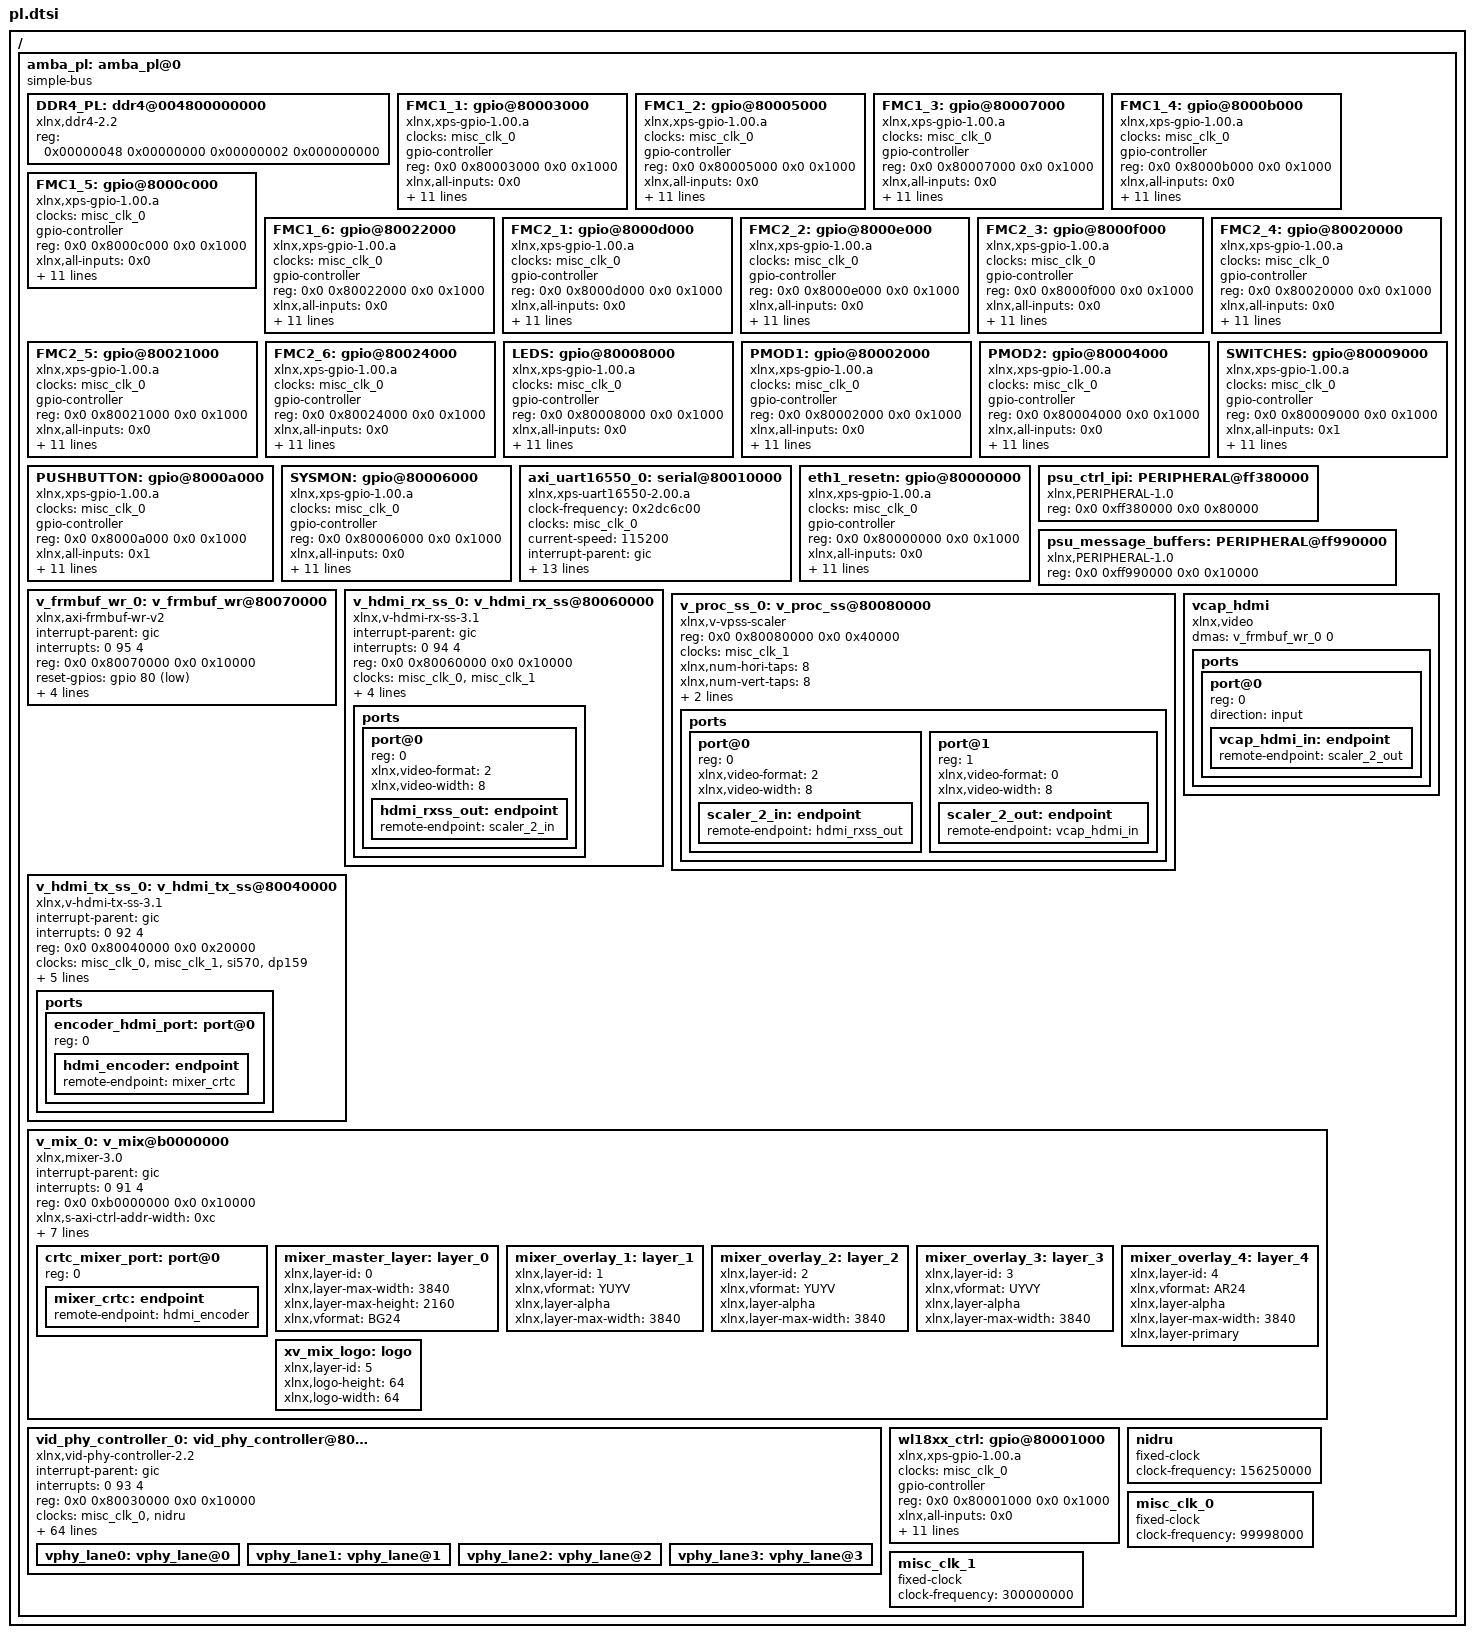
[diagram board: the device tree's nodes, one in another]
/*
 * CAUTION: This file is automatically generated by Xilinx.
 * Version:  
 * Today is: Thu Nov 15 16:52:35 2018
 */


/ {
	amba_pl: amba_pl@0 {
		#address-cells = <2>;
		#size-cells = <2>;
		compatible = "simple-bus";
		ranges ;
		DDR4_PL: ddr4@004800000000 {
			compatible = "xlnx,ddr4-2.2";
			device_type = "memory";
			reg = <0x00000048 0x00000000 0x00000002 0x000000000>;
		};
		FMC1_1: gpio@80003000 {
			#gpio-cells = <3>;
			clock-names = "s_axi_aclk";
			clocks = <&misc_clk_0>;
			compatible = "xlnx,xps-gpio-1.00.a";
			gpio-controller ;
			reg = <0x0 0x80003000 0x0 0x1000>;
			xlnx,all-inputs = <0x0>;
			xlnx,all-inputs-2 = <0x0>;
			xlnx,all-outputs = <0x0>;
			xlnx,all-outputs-2 = <0x0>;
			xlnx,dout-default = <0x00000000>;
			xlnx,dout-default-2 = <0x00000000>;
			xlnx,gpio-width = <0x20>;
			xlnx,gpio2-width = <0x20>;
			xlnx,interrupt-present = <0x0>;
			xlnx,is-dual = <0x0>;
			xlnx,tri-default = <0xFFFFFFFF>;
			xlnx,tri-default-2 = <0xFFFFFFFF>;
		};
		FMC1_2: gpio@80005000 {
			#gpio-cells = <3>;
			clock-names = "s_axi_aclk";
			clocks = <&misc_clk_0>;
			compatible = "xlnx,xps-gpio-1.00.a";
			gpio-controller ;
			reg = <0x0 0x80005000 0x0 0x1000>;
			xlnx,all-inputs = <0x0>;
			xlnx,all-inputs-2 = <0x0>;
			xlnx,all-outputs = <0x0>;
			xlnx,all-outputs-2 = <0x0>;
			xlnx,dout-default = <0x00000000>;
			xlnx,dout-default-2 = <0x00000000>;
			xlnx,gpio-width = <0x20>;
			xlnx,gpio2-width = <0x20>;
			xlnx,interrupt-present = <0x0>;
			xlnx,is-dual = <0x0>;
			xlnx,tri-default = <0xFFFFFFFF>;
			xlnx,tri-default-2 = <0xFFFFFFFF>;
		};
		FMC1_3: gpio@80007000 {
			#gpio-cells = <3>;
			clock-names = "s_axi_aclk";
			clocks = <&misc_clk_0>;
			compatible = "xlnx,xps-gpio-1.00.a";
			gpio-controller ;
			reg = <0x0 0x80007000 0x0 0x1000>;
			xlnx,all-inputs = <0x0>;
			xlnx,all-inputs-2 = <0x0>;
			xlnx,all-outputs = <0x0>;
			xlnx,all-outputs-2 = <0x0>;
			xlnx,dout-default = <0x00000000>;
			xlnx,dout-default-2 = <0x00000000>;
			xlnx,gpio-width = <0x20>;
			xlnx,gpio2-width = <0x20>;
			xlnx,interrupt-present = <0x0>;
			xlnx,is-dual = <0x0>;
			xlnx,tri-default = <0xFFFFFFFF>;
			xlnx,tri-default-2 = <0xFFFFFFFF>;
		};
		FMC1_4: gpio@8000b000 {
			#gpio-cells = <3>;
			clock-names = "s_axi_aclk";
			clocks = <&misc_clk_0>;
			compatible = "xlnx,xps-gpio-1.00.a";
			gpio-controller ;
			reg = <0x0 0x8000b000 0x0 0x1000>;
			xlnx,all-inputs = <0x0>;
			xlnx,all-inputs-2 = <0x0>;
			xlnx,all-outputs = <0x0>;
			xlnx,all-outputs-2 = <0x0>;
			xlnx,dout-default = <0x00000000>;
			xlnx,dout-default-2 = <0x00000000>;
			xlnx,gpio-width = <0x20>;
			xlnx,gpio2-width = <0x20>;
			xlnx,interrupt-present = <0x0>;
			xlnx,is-dual = <0x0>;
			xlnx,tri-default = <0xFFFFFFFF>;
			xlnx,tri-default-2 = <0xFFFFFFFF>;
		};
		FMC1_5: gpio@8000c000 {
			#gpio-cells = <3>;
			clock-names = "s_axi_aclk";
			clocks = <&misc_clk_0>;
			compatible = "xlnx,xps-gpio-1.00.a";
			gpio-controller ;
			reg = <0x0 0x8000c000 0x0 0x1000>;
			xlnx,all-inputs = <0x0>;
			xlnx,all-inputs-2 = <0x0>;
			xlnx,all-outputs = <0x0>;
			xlnx,all-outputs-2 = <0x0>;
			xlnx,dout-default = <0x00000000>;
			xlnx,dout-default-2 = <0x00000000>;
			xlnx,gpio-width = <0x20>;
			xlnx,gpio2-width = <0x20>;
			xlnx,interrupt-present = <0x0>;
			xlnx,is-dual = <0x0>;
			xlnx,tri-default = <0xFFFFFFFF>;
			xlnx,tri-default-2 = <0xFFFFFFFF>;
		};
		FMC1_6: gpio@80022000 {
			#gpio-cells = <3>;
			clock-names = "s_axi_aclk";
			clocks = <&misc_clk_0>;
			compatible = "xlnx,xps-gpio-1.00.a";
			gpio-controller ;
			reg = <0x0 0x80022000 0x0 0x1000>;
			xlnx,all-inputs = <0x0>;
			xlnx,all-inputs-2 = <0x0>;
			xlnx,all-outputs = <0x0>;
			xlnx,all-outputs-2 = <0x0>;
			xlnx,dout-default = <0x00000000>;
			xlnx,dout-default-2 = <0x00000000>;
			xlnx,gpio-width = <0xa>;
			xlnx,gpio2-width = <0x20>;
			xlnx,interrupt-present = <0x0>;
			xlnx,is-dual = <0x0>;
			xlnx,tri-default = <0xFFFFFFFF>;
			xlnx,tri-default-2 = <0xFFFFFFFF>;
		};
		FMC2_1: gpio@8000d000 {
			#gpio-cells = <3>;
			clock-names = "s_axi_aclk";
			clocks = <&misc_clk_0>;
			compatible = "xlnx,xps-gpio-1.00.a";
			gpio-controller ;
			reg = <0x0 0x8000d000 0x0 0x1000>;
			xlnx,all-inputs = <0x0>;
			xlnx,all-inputs-2 = <0x0>;
			xlnx,all-outputs = <0x0>;
			xlnx,all-outputs-2 = <0x0>;
			xlnx,dout-default = <0x00000000>;
			xlnx,dout-default-2 = <0x00000000>;
			xlnx,gpio-width = <0x20>;
			xlnx,gpio2-width = <0x20>;
			xlnx,interrupt-present = <0x0>;
			xlnx,is-dual = <0x0>;
			xlnx,tri-default = <0xFFFFFFFF>;
			xlnx,tri-default-2 = <0xFFFFFFFF>;
		};
		FMC2_2: gpio@8000e000 {
			#gpio-cells = <3>;
			clock-names = "s_axi_aclk";
			clocks = <&misc_clk_0>;
			compatible = "xlnx,xps-gpio-1.00.a";
			gpio-controller ;
			reg = <0x0 0x8000e000 0x0 0x1000>;
			xlnx,all-inputs = <0x0>;
			xlnx,all-inputs-2 = <0x0>;
			xlnx,all-outputs = <0x0>;
			xlnx,all-outputs-2 = <0x0>;
			xlnx,dout-default = <0x00000000>;
			xlnx,dout-default-2 = <0x00000000>;
			xlnx,gpio-width = <0x20>;
			xlnx,gpio2-width = <0x20>;
			xlnx,interrupt-present = <0x0>;
			xlnx,is-dual = <0x0>;
			xlnx,tri-default = <0xFFFFFFFF>;
			xlnx,tri-default-2 = <0xFFFFFFFF>;
		};
		FMC2_3: gpio@8000f000 {
			#gpio-cells = <3>;
			clock-names = "s_axi_aclk";
			clocks = <&misc_clk_0>;
			compatible = "xlnx,xps-gpio-1.00.a";
			gpio-controller ;
			reg = <0x0 0x8000f000 0x0 0x1000>;
			xlnx,all-inputs = <0x0>;
			xlnx,all-inputs-2 = <0x0>;
			xlnx,all-outputs = <0x0>;
			xlnx,all-outputs-2 = <0x0>;
			xlnx,dout-default = <0x00000000>;
			xlnx,dout-default-2 = <0x00000000>;
			xlnx,gpio-width = <0x20>;
			xlnx,gpio2-width = <0x20>;
			xlnx,interrupt-present = <0x0>;
			xlnx,is-dual = <0x0>;
			xlnx,tri-default = <0xFFFFFFFF>;
			xlnx,tri-default-2 = <0xFFFFFFFF>;
		};
		FMC2_4: gpio@80020000 {
			#gpio-cells = <3>;
			clock-names = "s_axi_aclk";
			clocks = <&misc_clk_0>;
			compatible = "xlnx,xps-gpio-1.00.a";
			gpio-controller ;
			reg = <0x0 0x80020000 0x0 0x1000>;
			xlnx,all-inputs = <0x0>;
			xlnx,all-inputs-2 = <0x0>;
			xlnx,all-outputs = <0x0>;
			xlnx,all-outputs-2 = <0x0>;
			xlnx,dout-default = <0x00000000>;
			xlnx,dout-default-2 = <0x00000000>;
			xlnx,gpio-width = <0x20>;
			xlnx,gpio2-width = <0x20>;
			xlnx,interrupt-present = <0x0>;
			xlnx,is-dual = <0x0>;
			xlnx,tri-default = <0xFFFFFFFF>;
			xlnx,tri-default-2 = <0xFFFFFFFF>;
		};
		FMC2_5: gpio@80021000 {
			#gpio-cells = <3>;
			clock-names = "s_axi_aclk";
			clocks = <&misc_clk_0>;
			compatible = "xlnx,xps-gpio-1.00.a";
			gpio-controller ;
			reg = <0x0 0x80021000 0x0 0x1000>;
			xlnx,all-inputs = <0x0>;
			xlnx,all-inputs-2 = <0x0>;
			xlnx,all-outputs = <0x0>;
			xlnx,all-outputs-2 = <0x0>;
			xlnx,dout-default = <0x00000000>;
			xlnx,dout-default-2 = <0x00000000>;
			xlnx,gpio-width = <0x20>;
			xlnx,gpio2-width = <0x20>;
			xlnx,interrupt-present = <0x0>;
			xlnx,is-dual = <0x0>;
			xlnx,tri-default = <0xFFFFFFFF>;
			xlnx,tri-default-2 = <0xFFFFFFFF>;
		};
		FMC2_6: gpio@80024000 {
			#gpio-cells = <3>;
			clock-names = "s_axi_aclk";
			clocks = <&misc_clk_0>;
			compatible = "xlnx,xps-gpio-1.00.a";
			gpio-controller ;
			reg = <0x0 0x80024000 0x0 0x1000>;
			xlnx,all-inputs = <0x0>;
			xlnx,all-inputs-2 = <0x0>;
			xlnx,all-outputs = <0x0>;
			xlnx,all-outputs-2 = <0x0>;
			xlnx,dout-default = <0x00000000>;
			xlnx,dout-default-2 = <0x00000000>;
			xlnx,gpio-width = <0xa>;
			xlnx,gpio2-width = <0x20>;
			xlnx,interrupt-present = <0x0>;
			xlnx,is-dual = <0x0>;
			xlnx,tri-default = <0xFFFFFFFF>;
			xlnx,tri-default-2 = <0xFFFFFFFF>;
		};
		LEDS: gpio@80008000 {
			#gpio-cells = <3>;
			clock-names = "s_axi_aclk";
			clocks = <&misc_clk_0>;
			compatible = "xlnx,xps-gpio-1.00.a";
			gpio-controller ;
			reg = <0x0 0x80008000 0x0 0x1000>;
			xlnx,all-inputs = <0x0>;
			xlnx,all-inputs-2 = <0x0>;
			xlnx,all-outputs = <0x1>;
			xlnx,all-outputs-2 = <0x0>;
			xlnx,dout-default = <0xFFFFFFFF>;
			xlnx,dout-default-2 = <0x00000000>;
			xlnx,gpio-width = <0x3>;
			xlnx,gpio2-width = <0x20>;
			xlnx,interrupt-present = <0x0>;
			xlnx,is-dual = <0x0>;
			xlnx,tri-default = <0xFFFFFFFF>;
			xlnx,tri-default-2 = <0xFFFFFFFF>;
		};
		/*
		PCIE_ROOT: axi-pcie@a0000000 {
			status = "disabled";
			#address-cells = <3>;
			#interrupt-cells = <1>;
			#size-cells = <2>;
			compatible = "xlnx,xdma-host-3.00";
			device_type = "pci";
			interrupt-map = <0 0 0 1 &pcie_intc_0 1>, <0 0 0 2 &pcie_intc_0 2>, <0 0 0 3 &pcie_intc_0 3>, <0 0 0 4 &pcie_intc_0 4>;
			interrupt-map-mask = <0 0 0 7>;
			interrupt-names = "misc", "msi0", "msi1";
			interrupt-parent = <&gic>;
			interrupts = <0 90 4>;
			ranges = <0x02000000 0x00000000 0x80100000 0x0 0xA0000000 0x00000000 0x00100000>;
			reg = <0x00000004 0x00000000 0x0 0x20000000>;
			pcie_intc_0: interrupt-controller {
				#address-cells = <0>;
				#interrupt-cells = <1>;
				interrupt-controller ;
			};
		};
		*/
		PMOD1: gpio@80002000 {
			#gpio-cells = <3>;
			clock-names = "s_axi_aclk";
			clocks = <&misc_clk_0>;
			compatible = "xlnx,xps-gpio-1.00.a";
			gpio-controller ;
			reg = <0x0 0x80002000 0x0 0x1000>;
			xlnx,all-inputs = <0x0>;
			xlnx,all-inputs-2 = <0x0>;
			xlnx,all-outputs = <0x0>;
			xlnx,all-outputs-2 = <0x0>;
			xlnx,dout-default = <0x00000000>;
			xlnx,dout-default-2 = <0x00000000>;
			xlnx,gpio-width = <0x8>;
			xlnx,gpio2-width = <0x20>;
			xlnx,interrupt-present = <0x0>;
			xlnx,is-dual = <0x0>;
			xlnx,tri-default = <0xFFFFFFFF>;
			xlnx,tri-default-2 = <0xFFFFFFFF>;
		};
		PMOD2: gpio@80004000 {
			#gpio-cells = <3>;
			clock-names = "s_axi_aclk";
			clocks = <&misc_clk_0>;
			compatible = "xlnx,xps-gpio-1.00.a";
			gpio-controller ;
			reg = <0x0 0x80004000 0x0 0x1000>;
			xlnx,all-inputs = <0x0>;
			xlnx,all-inputs-2 = <0x0>;
			xlnx,all-outputs = <0x0>;
			xlnx,all-outputs-2 = <0x0>;
			xlnx,dout-default = <0x00000000>;
			xlnx,dout-default-2 = <0x00000000>;
			xlnx,gpio-width = <0x8>;
			xlnx,gpio2-width = <0x20>;
			xlnx,interrupt-present = <0x0>;
			xlnx,is-dual = <0x0>;
			xlnx,tri-default = <0xFFFFFFFF>;
			xlnx,tri-default-2 = <0xFFFFFFFF>;
		};
		PUSHBUTTON: gpio@8000a000 {
			#gpio-cells = <3>;
			clock-names = "s_axi_aclk";
			clocks = <&misc_clk_0>;
			compatible = "xlnx,xps-gpio-1.00.a";
			gpio-controller ;
			reg = <0x0 0x8000a000 0x0 0x1000>;
			xlnx,all-inputs = <0x1>;
			xlnx,all-inputs-2 = <0x0>;
			xlnx,all-outputs = <0x0>;
			xlnx,all-outputs-2 = <0x0>;
			xlnx,dout-default = <0x00000000>;
			xlnx,dout-default-2 = <0x00000000>;
			xlnx,gpio-width = <0x1>;
			xlnx,gpio2-width = <0x20>;
			xlnx,interrupt-present = <0x0>;
			xlnx,is-dual = <0x0>;
			xlnx,tri-default = <0xFFFFFFFF>;
			xlnx,tri-default-2 = <0xFFFFFFFF>;
		};
		SWITCHES: gpio@80009000 {
			#gpio-cells = <3>;
			clock-names = "s_axi_aclk";
			clocks = <&misc_clk_0>;
			compatible = "xlnx,xps-gpio-1.00.a";
			gpio-controller ;
			reg = <0x0 0x80009000 0x0 0x1000>;
			xlnx,all-inputs = <0x1>;
			xlnx,all-inputs-2 = <0x0>;
			xlnx,all-outputs = <0x0>;
			xlnx,all-outputs-2 = <0x0>;
			xlnx,dout-default = <0x00000000>;
			xlnx,dout-default-2 = <0x00000000>;
			xlnx,gpio-width = <0x4>;
			xlnx,gpio2-width = <0x20>;
			xlnx,interrupt-present = <0x0>;
			xlnx,is-dual = <0x0>;
			xlnx,tri-default = <0xFFFFFFFF>;
			xlnx,tri-default-2 = <0xFFFFFFFF>;
		};
		SYSMON: gpio@80006000 {
			#gpio-cells = <3>;
			clock-names = "s_axi_aclk";
			clocks = <&misc_clk_0>;
			compatible = "xlnx,xps-gpio-1.00.a";
			gpio-controller ;
			reg = <0x0 0x80006000 0x0 0x1000>;
			xlnx,all-inputs = <0x0>;
			xlnx,all-inputs-2 = <0x0>;
			xlnx,all-outputs = <0x0>;
			xlnx,all-outputs-2 = <0x0>;
			xlnx,dout-default = <0x00000000>;
			xlnx,dout-default-2 = <0x00000000>;
			xlnx,gpio-width = <0x8>;
			xlnx,gpio2-width = <0x20>;
			xlnx,interrupt-present = <0x0>;
			xlnx,is-dual = <0x0>;
			xlnx,tri-default = <0xFFFFFFFF>;
			xlnx,tri-default-2 = <0xFFFFFFFF>;
		};
		axi_uart16550_0: serial@80010000 {
			clock-frequency = <0x2dc6c00>;
			clock-names = "s_axi_aclk";
			clocks = <&misc_clk_0>;
			compatible = "xlnx,xps-uart16550-2.00.a", "ns16550a";
			current-speed = <115200>;
			device_type = "serial";
			interrupt-names = "ip2intc_irpt";
			interrupt-parent = <&gic>;
			interrupts = <0 89 4>;
			port-number = <1>;
			reg = <0x0 0x80010000 0x0 0x10000>;
			reg-offset = <0x1000>;
			reg-shift = <2>;
			xlnx,external-xin-clk-hz = <0x2dc6c00>;
			xlnx,external-xin-clk-hz-d = <0x30>;
			xlnx,has-external-rclk = <0x0>;
			xlnx,has-external-xin = <0x1>;
			xlnx,is-a-16550 = <0x1>;
			xlnx,s-axi-aclk-freq-hz-d = "99.998";
			xlnx,use-modem-ports = <0x1>;
			xlnx,use-user-ports = <0x1>;
		};
		eth1_resetn: gpio@80000000 {
			#gpio-cells = <3>;
			clock-names = "s_axi_aclk";
			clocks = <&misc_clk_0>;
			compatible = "xlnx,xps-gpio-1.00.a";
			gpio-controller ;
			reg = <0x0 0x80000000 0x0 0x1000>;
			xlnx,all-inputs = <0x0>;
			xlnx,all-inputs-2 = <0x0>;
			xlnx,all-outputs = <0x1>;
			xlnx,all-outputs-2 = <0x0>;
			xlnx,dout-default = <0xFFFFFFFF>;
			xlnx,dout-default-2 = <0x00000000>;
			xlnx,gpio-width = <0x1>;
			xlnx,gpio2-width = <0x20>;
			xlnx,interrupt-present = <0x0>;
			xlnx,is-dual = <0x0>;
			xlnx,tri-default = <0xFFFFFFFF>;
			xlnx,tri-default-2 = <0xFFFFFFFF>;
		};
		psu_ctrl_ipi: PERIPHERAL@ff380000 {
			compatible = "xlnx,PERIPHERAL-1.0";
			reg = <0x0 0xff380000 0x0 0x80000>;
		};
		psu_message_buffers: PERIPHERAL@ff990000 {
			compatible = "xlnx,PERIPHERAL-1.0";
			reg = <0x0 0xff990000 0x0 0x10000>;
		};
		v_frmbuf_wr_0: v_frmbuf_wr@80070000 {
			#dma-cells = <1>;
			//compatible = "xlnx,v-frmbuf-wr-2.1";
			compatible = "xlnx,axi-frmbuf-wr-v2";
			interrupt-names = "interrupt";
			interrupt-parent = <&gic>;
			interrupts = <0 95 4>;
			reg = <0x0 0x80070000 0x0 0x10000>;
			reset-gpios = <&gpio 80 1>;
			
			xlnx,dma-addr-width = <32>;
			xlnx,s-axi-ctrl-addr-width = <0x20>;
			xlnx,s-axi-ctrl-data-width = <0x20>;
			xlnx,vid-formats = "yuyv","uyvy","y8";
		};
		v_hdmi_rx_ss_0: v_hdmi_rx_ss@80060000 {
			compatible = "xlnx,v-hdmi-rx-ss-3.1";
			interrupt-names = "irq";
			interrupt-parent = <&gic>;
			interrupts = <0 94 4>;
			reg = <0x0 0x80060000 0x0 0x10000>;
			
			clocks = <&misc_clk_0>, <&misc_clk_1>;
			clock-names = "axi-lite", "video";
			
			phy-names = "hdmi-phy0", "hdmi-phy1", "hdmi-phy2";
			phys = <&vphy_lane0 0 1 1 0>, <&vphy_lane1 0 1 1 0>, <&vphy_lane2 0 1 1 0>;
			
			xlnx,edid-ram-size = <0x100>;
			xlnx,input-pixels-per-clock = <0x2>;
			/*
			xlnx,add-mark-dbg = "false";
			xlnx,addr-width = <0xa>;
			xlnx,cd-invert = "false";
			
			xlnx,exdes-axilite-freq = <0x64>;
			xlnx,exdes-nidru = "true";
			xlnx,exdes-rx-pll-selection = <0x0>;
			xlnx,exdes-topology = <0x0>;
			xlnx,exdes-tx-pll-selection = <0x1>;
			xlnx,hdmi-fast-switch = "false";
			xlnx,hdmi-version = <0x3>;
			xlnx,hpd-invert = "false";
			xlnx,include-hdcp-1-4 = "false";
			xlnx,include-hdcp-2-2 = "false";
			xlnx,include-low-reso-vid = "false";
			xlnx,include-yuv420-sup = "false";
			
			xlnx,max-bits-per-component = <0x8>;
			xlnx,validation-enable = "false";
			xlnx,vid-interface = <0x0>;
			*/
			
			ports {
				#address-cells = <1>;
				#size-cells = <0>;

				port@0 {
					reg = <0>;

					xlnx,video-format = <2>;
					xlnx,video-width = <8>;

					hdmi_rxss_out: endpoint {
						remote-endpoint = <&scaler_2_in>;
					};
				};
			};
		};
		v_proc_ss_0: v_proc_ss@80080000 {
			//compatible = "xlnx,v-proc-ss-2.0";
			compatible = "xlnx,v-vpss-scaler";
			reg = <0x0 0x80080000 0x0 0x40000>;
			/*
			xlnx,aximm-addr-width = <0x20>;
			xlnx,aximm-burst-length = <0x10>;
			xlnx,aximm-num-outstanding = <0x10>;
			xlnx,chroma-algorithm = <0x2>;
			xlnx,colorspace-support = <0x0>;
			xlnx,csc-enable-422 = "true";
			xlnx,csc-enable-window = "true";
			xlnx,deint-motion-adaptive = "true";
			xlnx,enable-csc = "true";
			xlnx,enable-dma = "true";
			xlnx,enable-interlaced = "true";
			xlnx,h-chroma-algorithm = <0x2>;
			xlnx,h-chroma-taps = <0x4>;
			xlnx,h-scaler-phases = <0x40>;
			xlnx,h-scaler-taps = <0x8>;
			xlnx,max-cols = <0xf00>;
			xlnx,max-data-width = <0x8>;
			xlnx,max-rows = <0x870>;
			xlnx,num-video-components = <0x3>;
			xlnx,samples-per-clk = <0x2>;
			xlnx,scaler-algorithm = <0x2>;
			xlnx,scaler-enable-422 = "true";
			xlnx,topology = <0x0>;
			xlnx,use-uram = <0x0>;
			xlnx,v-chroma-algorithm = <0x2>;
			xlnx,v-chroma-taps = <0x4>;
			xlnx,v-scaler-phases = <0x40>;
			xlnx,v-scaler-taps = <0x8>;
			*/
			clocks = <&misc_clk_1>;
			xlnx,num-hori-taps = <8>;
			xlnx,num-vert-taps = <8>;
			xlnx,pix-per-clk = <2>;
			reset-gpios = <&gpio 78 1>;
			
			ports {
				#address-cells = <1>;
				#size-cells = <0>;

				port@0 {
					reg = <0>;

					xlnx,video-format = <2>;
					xlnx,video-width = <8>;

					scaler_2_in: endpoint {
						remote-endpoint = <&hdmi_rxss_out>;
					};
				};
				port@1 {
					reg = <1>;

					xlnx,video-format = <0>;
					xlnx,video-width = <8>;

					scaler_2_out: endpoint {
						remote-endpoint = <&vcap_hdmi_in>;
					};
				};
			};
		};
		vcap_hdmi {
			compatible = "xlnx,video";
			dmas = <&v_frmbuf_wr_0 0>;
			dma-names = "port0";

			ports {
				#address-cells = <1>;
				#size-cells = <0>;

				port@0 {
					reg = <0>;
					direction = "input";
					vcap_hdmi_in: endpoint {
						remote-endpoint = <&scaler_2_out>;
					};
				};
			};
		};
		v_hdmi_tx_ss_0: v_hdmi_tx_ss@80040000 {
			compatible = "xlnx,v-hdmi-tx-ss-3.1";
			
			interrupt-names = "hdmi-txss";
			interrupt-parent = <&gic>;
			interrupts = <0 92 4>;
			
			reg = <0x0 0x80040000 0x0 0x20000>;
			/*
			xlnx,add-mark-dbg = "false";
			xlnx,addr-width = <0xa>;
			xlnx,exdes-axilite-freq = <0x64>;
			xlnx,exdes-nidru = "false";
			xlnx,exdes-rx-pll-selection = <0x0>;
			xlnx,exdes-topology = <0x1>;
			xlnx,exdes-tx-pll-selection = <0x6>;
			xlnx,hdmi-fast-switch = "false";
			xlnx,hdmi-version = <0x3>;
			xlnx,hpd-invert = "false";
			xlnx,hysteresis-level = <0xc>;
			xlnx,include-hdcp-1-4 = "false";
			xlnx,include-hdcp-2-2 = "false";
			xlnx,include-low-reso-vid = "false";
			xlnx,include-yuv420-sup = "true";
			
			xlnx,validation-enable = "false";
			xlnx,vid-interface = <0x0>;
			xlnx,video-mask-enable = <0x1>;
			*/
			
			clocks = <&misc_clk_0>, <&misc_clk_1>, <&si570>, <&dp159>;
			clock-names = "axi-lite", "video", "txref-clk", "retimer-clk";

			phy-names = "hdmi-phy0", "hdmi-phy1", "hdmi-phy2";
			phys = <&vphy_lane0 0 1 1 1>, <&vphy_lane1 0 1 1 1>, <&vphy_lane2 0 1 1 1>;

			xlnx,output-fmt = "rgb";
			xlnx,input-pixels-per-clock = <0x2>;
			xlnx,max-bits-per-component = <0x8>;
			
			ports {
				#address-cells = <1>;
				#size-cells = <0>;
				encoder_hdmi_port: port@0 {
					reg = <0>;
					hdmi_encoder: endpoint {
						remote-endpoint = <&mixer_crtc>;
					};
				};
			};
		};
		v_mix_0: v_mix@b0000000 {
			compatible = "xlnx,mixer-3.0";
			interrupt-names = "hdmi-v-mix";
			interrupt-parent = <&gic>;
			interrupts = <0 91 4>;
			reg = <0x0 0xb0000000 0x0 0x10000>;
			xlnx,s-axi-ctrl-addr-width = <0xc>;
			xlnx,s-axi-ctrl-data-width = <0x20>;
			reset-gpios = <&gpio 79 1>;
			clocks = <&si570>;
			xlnx,dma-addr-width=<32>;

			xlnx,bpc = <8>;
			xlnx,ppc = <2>;
			xlnx,num-layers = <5>;

			crtc_mixer_port: port@0 {
					reg = <0>;
					mixer_crtc: endpoint {
					remote-endpoint = <&hdmi_encoder>;
				};
			};

			mixer_master_layer: layer_0 {
				xlnx,layer-id = <0>;
				xlnx,layer-max-width = <3840>;
				xlnx,layer-max-height = <2160>;
				xlnx,vformat = "BG24";
			};
			mixer_overlay_1: layer_1 {
				xlnx,layer-id = <1>;
				xlnx,vformat = "YUYV";
				xlnx,layer-alpha;
				xlnx,layer-max-width = <3840>;
			};
			mixer_overlay_2: layer_2 {
				xlnx,layer-id = <2>;
				xlnx,vformat = "YUYV";
				xlnx,layer-alpha;
				xlnx,layer-max-width = <3840>;
			};
			mixer_overlay_3: layer_3 {
				xlnx,layer-id = <3>;
				xlnx,vformat = "UYVY";
				xlnx,layer-alpha;
				xlnx,layer-max-width = <3840>;
			};
			mixer_overlay_4: layer_4 {
				xlnx,layer-id = <4>;
				xlnx,vformat = "AR24";
				xlnx,layer-alpha;
				xlnx,layer-max-width = <3840>;
				xlnx,layer-primary;
			};
			xv_mix_logo: logo {
				xlnx,layer-id = <5>;
				xlnx,logo-height = <64>;
				xlnx,logo-width = <64>;
			};
		};
		vid_phy_controller_0: vid_phy_controller@80030000 {
			compatible = "xlnx,vid-phy-controller-2.2";
			interrupt-names = "hdmi-vid-phy";
			interrupt-parent = <&gic>;
			interrupts = <0 93 4>;
			reg = <0x0 0x80030000 0x0 0x10000>;
			
			clocks = <&misc_clk_0>, <&nidru>;
			clock-names = "axi-lite", "dru-clk";
			
			xlnx,axi4lite-enable = "true";
			xlnx,component-name = "design_1_vid_phy_controller_0_0";
			xlnx,device = "xczu19eg";
			xlnx,dru-gain-g1 = <0x9>;
			xlnx,dru-gain-g1-p = <0x10>;
			xlnx,dru-gain-g2 = <0x4>;
			xlnx,dru-refclk-fabric-buffer = "none";
			xlnx,err-irq-en = <0x0>;
			xlnx,for-upgrade-architecture = "zynquplus";
			xlnx,for-upgrade-device = "xczu19eg";
			xlnx,for-upgrade-maxoptvol = "0.876";
			xlnx,for-upgrade-package = "ffvb1517";
			xlnx,for-upgrade-part = "xczu19eg-ffvb1517-2-i";
			xlnx,for-upgrade-refvol = "0.850";
			xlnx,for-upgrade-speedgrade = "-2";
			xlnx,hdmi-fast-switch = <0x1>;
			xlnx,input-pixels-per-clock = <0x2>;
			xlnx,int-hdmi-ver-cmptble = <0x3>;
			
			xlnx,nidru = <0x1>;
			xlnx,nidru-refclk-sel = <0x5>;
			xlnx,rx-gt-debug-ports = "false";
			xlnx,rx-no-of-channels = <0x3>;
			xlnx,rx-outclk-buffer = "none";
			xlnx,rx-pll-selection = <0x6>;
			xlnx,rx-protocol = <0x1>;
			xlnx,rx-refclk-sel = <0x0>;
			xlnx,rx-sb-ports = "true";
			xlnx,rx-tmds-clk-buffer = "bufg";
			xlnx,rx-video-clk-buffer = "bufg";
			xlnx,silicon-revision = <0x0>;
			xlnx,speedgrade = "-2";
			xlnx,supportlevel = <0x1>;
			
			xlnx,transceivercontrol = "false";
			xlnx,tx-gt-debug-ports = "false";
			xlnx,tx-no-of-channels = <0x3>;
			xlnx,tx-outclk-buffer = "none";
			xlnx,tx-pll-selection = <0x0>;
			xlnx,tx-protocol = <0x1>;
			xlnx,tx-refclk-fabric-buffer = "none";
			xlnx,tx-refclk-sel = <0x4>;
			xlnx,tx-sb-ports = "true";
			xlnx,tx-tmds-clk-buffer = "bufg";
			xlnx,tx-video-clk-buffer = "bufg";
			xlnx,txpi-port-en = "false";
			xlnx,txrefclk-rdy-invert = <0x1>;
			xlnx,use-gt-ch4-hdmi = <0x0>;
			xlnx,use-oddr-for-tmds-clkout = "true";
			
			xlnx,vid-phy-axi4lite-addr-width = <0xa>;
			xlnx,vid-phy-axi4lite-data-width = <0x20>;
			xlnx,vid-phy-control-sb-rx-tdata-width = <0x1>;
			xlnx,vid-phy-control-sb-tx-tdata-width = <0x1>;
			xlnx,vid-phy-rx-axi4s-ch-int-tdata-width = <0x14>;
			xlnx,vid-phy-rx-axi4s-ch-tdata-width = <0x14>;
			xlnx,vid-phy-rx-axi4s-ch-tuser-width = <0x1>;
			xlnx,vid-phy-status-sb-rx-tdata-width = <0x2>;
			xlnx,vid-phy-status-sb-tx-tdata-width = <0x2>;
			xlnx,vid-phy-tx-axi4s-ch-int-tdata-width = <0x14>;
			xlnx,vid-phy-tx-axi4s-ch-tdata-width = <0x14>;
			xlnx,vid-phy-tx-axi4s-ch-tuser-width = <0x1>;
			xlnx,viper-reg = "false";
			
			xlnx,transceiver-type = <0x5>;
			xlnx,tx-buffer-bypass = <0x1>;
			xlnx,transceiver-width = <0x2>;

			vphy_lane0: vphy_lane@0 {
				#phy-cells = <4>;
			};
			vphy_lane1: vphy_lane@1 {
				#phy-cells = <4>;
			};
			vphy_lane2: vphy_lane@2 {
				#phy-cells = <4>;
			};
			vphy_lane3: vphy_lane@3 {
				#phy-cells = <4>;
			};
		};
		wl18xx_ctrl: gpio@80001000 {
			#gpio-cells = <3>;
			clock-names = "s_axi_aclk";
			clocks = <&misc_clk_0>;
			compatible = "xlnx,xps-gpio-1.00.a";
			gpio-controller ;
			reg = <0x0 0x80001000 0x0 0x1000>;
			xlnx,all-inputs = <0x0>;
			xlnx,all-inputs-2 = <0x0>;
			xlnx,all-outputs = <0x1>;
			xlnx,all-outputs-2 = <0x0>;
			xlnx,dout-default = <0x00000000>;
			xlnx,dout-default-2 = <0x00000000>;
			xlnx,gpio-width = <0x2>;
			xlnx,gpio2-width = <0x20>;
			xlnx,interrupt-present = <0x0>;
			xlnx,is-dual = <0x0>;
			xlnx,tri-default = <0xFFFFFFFF>;
			xlnx,tri-default-2 = <0xFFFFFFFF>;
		};
		nidru: nidru {
			#clock-cells = <0>;
			clock-frequency = <156250000>;
			compatible = "fixed-clock";
		};
		misc_clk_0: misc_clk_0 {
			#clock-cells = <0>;
			clock-frequency = <99998000>;
			compatible = "fixed-clock";
		};
		misc_clk_1: misc_clk_1 {
			#clock-cells = <0>;
			clock-frequency = <300000000>;
			compatible = "fixed-clock";
		};
	};
};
